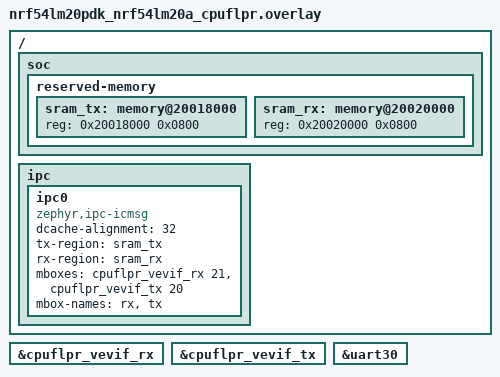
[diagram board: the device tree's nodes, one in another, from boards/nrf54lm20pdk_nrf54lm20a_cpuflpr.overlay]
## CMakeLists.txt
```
#
# Copyright (c) 2022 Nordic Semiconductor
#
# SPDX-License-Identifier: LicenseRef-Nordic-5-Clause
#

cmake_minimum_required(VERSION 3.20.0)

find_package(Zephyr REQUIRED HINTS $ENV{ZEPHYR_BASE})
project(event_manager_proxy_remote)

add_subdirectory("../common_events" "${CMAKE_CURRENT_BINARY_DIR}/common_events")
add_subdirectory("../modules"       "${CMAKE_CURRENT_BINARY_DIR}/modules")

target_sources(app PRIVATE src/main.c)
```

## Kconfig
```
#
# Copyright (c) 2022 Nordic Semiconductor ASA
#
# SPDX-License-Identifier: LicenseRef-Nordic-5-Clause
#

menu "Zephyr Kernel"
source "Kconfig.zephyr"
endmenu

menu "Event manager proxy sample application settings"
rsource "../common_events/Kconfig"
rsource "../modules/Kconfig"
endmenu
```

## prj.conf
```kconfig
#
# Copyright (c) 2022 Nordic Semiconductor ASA
#
# SPDX-License-Identifier: LicenseRef-Nordic-5-Clause
#
# Enabling assert
CONFIG_ASSERT=y

# Logger configuration
CONFIG_LOG=y
CONFIG_LOG_BACKEND_UART=y

# Configuration required by Event Manager
CONFIG_APP_EVENT_MANAGER=y
CONFIG_EVENT_MANAGER_PROXY=y
CONFIG_HEAP_MEM_POOL_SIZE=4096
CONFIG_REBOOT=y

CONFIG_PRINTK=y

CONFIG_IPC_SERVICE=y
CONFIG_MBOX=y

# Simplify debugging
CONFIG_RESET_ON_FATAL_ERROR=n

###################################
# Application configuration
###################################

CONFIG_APP_MODULE_CONTROLLER_ENABLE=y
CONFIG_APP_MODULE_SENSOR_SIMULATED_ENABLE=y
```

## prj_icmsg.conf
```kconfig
#
# Copyright (c) 2022 Nordic Semiconductor ASA
#
# SPDX-License-Identifier: LicenseRef-Nordic-5-Clause
#
# Enabling assert
CONFIG_ASSERT=y

# Logger configuration
CONFIG_LOG=y
CONFIG_LOG_DEFAULT_LEVEL=2
CONFIG_LOG_BACKEND_UART=y

# Configuration required by Event Manager
CONFIG_APP_EVENT_MANAGER=y
CONFIG_EVENT_MANAGER_PROXY=y
CONFIG_HEAP_MEM_POOL_SIZE=4096
CONFIG_REBOOT=y

CONFIG_PRINTK=y

CONFIG_IPC_SERVICE=y
CONFIG_MBOX=y

# Simplify debugging
CONFIG_RESET_ON_FATAL_ERROR=n

###################################
# Application configuration
###################################

CONFIG_APP_MODULE_CONTROLLER_ENABLE=y
CONFIG_APP_MODULE_SENSOR_SIMULATED_ENABLE=y
```

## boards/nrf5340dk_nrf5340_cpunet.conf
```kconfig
#
# Copyright (c) 2024 Nordic Semiconductor ASA
#
# SPDX-License-Identifier: LicenseRef-Nordic-5-Clause
#
################################################################################

CONFIG_OPENAMP_MASTER=n
```

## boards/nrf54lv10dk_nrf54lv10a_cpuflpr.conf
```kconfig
#
# Copyright (c) 2024 Nordic Semiconductor ASA
#
# SPDX-License-Identifier: LicenseRef-Nordic-5-Clause
#
################################################################################

CONFIG_LOG=y
CONFIG_LOG_MODE_MINIMAL=y
CONFIG_ASSERT=n
CONFIG_LOG_BACKEND_UART=n

CONFIG_BOOT_BANNER=n
CONFIG_EARLY_CONSOLE=y
CONFIG_HEAP_MEM_POOL_SIZE=1024

CONFIG_SIZE_OPTIMIZATIONS=y
```

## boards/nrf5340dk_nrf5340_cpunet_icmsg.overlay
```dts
/*
 * Copyright (c) 2022 Nordic Semiconductor ASA
 *
 * SPDX-License-Identifier: LicenseRef-Nordic-5-Clause
 */

/delete-node/ &ipc0;
/delete-node/ &sram0_shared;

/ {
	chosen {
		/delete-property/ zephyr,ipc_shm;
	};

	reserved-memory {
		#address-cells = <1>;
		#size-cells = <1>;

		sram_rx: memory@20070000 {
			reg = <0x20070000 0x0800>;
		};

		sram_tx: memory@20078000 {
			reg = <0x20078000 0x0800>;
		};
	};

	ipc0: ipc0 {
		compatible = "zephyr,ipc-icmsg";
		tx-region = <&sram_tx>;
		rx-region = <&sram_rx>;
		mboxes = <&mbox 0>, <&mbox 1>;
		mbox-names = "rx", "tx";
		status = "okay";
	};
};
```

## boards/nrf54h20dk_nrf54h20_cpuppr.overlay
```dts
/*
 * Copyright (c) 2024 Nordic Semiconductor ASA
 *
 * SPDX-License-Identifier: LicenseRef-Nordic-5-Clause
 */

/* Enabled nodes required by IPC
 * Two mboxes, one for each sides and one ipc instance
 */

&cpuppr_vevif {
	status = "okay";
};

&cpuapp_bellboard {
	status = "okay";
};

ipc0: &cpuapp_cpuppr_ipc {
	status = "okay";
};

&uart135 {
	/delete-property/ hw-flow-control;
};
```

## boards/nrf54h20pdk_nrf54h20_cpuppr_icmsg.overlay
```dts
/*
 * Copyright (c) 2024 Nordic Semiconductor ASA
 *
 * SPDX-License-Identifier: LicenseRef-Nordic-5-Clause
 */

/* Enabled nodes required by IPC
 * Two mboxes, one for each sides and one ipc instance
 */

&cpuppr_vevif {
	status = "okay";
};

&cpuapp_bellboard {
	status = "okay";
};

ipc0: &cpuapp_cpuppr_ipc {
	status = "okay";
};
```

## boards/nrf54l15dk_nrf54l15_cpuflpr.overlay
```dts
/*
 * Copyright (c) 2025 Nordic Semiconductor ASA
 *
 * SPDX-License-Identifier: LicenseRef-Nordic-5-Clause
 */

/ {
	reserved-memory {
		#address-cells = <1>;
		#size-cells = <1>;
		ranges;

		sram_tx: memory@20017c00 {
			reg = <0x20017c00 0x8000>;
		};

		sram_rx: memory@2001fc00 {
			reg = <0x2001fc00 0x8000>;
		};
	};

	ipc {
		ipc0: ipc0 {
			compatible = "zephyr,ipc-icmsg";
			/delete-property/ tx-blocks;
			/delete-property/ rx-blocks;
			dcache-alignment = <32>;
			tx-region = <&sram_tx>;
			rx-region = <&sram_rx>;
			mboxes = <&cpuflpr_vevif_rx 21>, <&cpuflpr_vevif_tx 20>;
			mbox-names = "rx", "tx";
			status = "okay";
		};
	};
};

&cpuflpr_vevif_rx {
	status = "okay";
};

&cpuflpr_vevif_tx {
	status = "okay";
};

&uart30 {
	/delete-property/ hw-flow-control;
};
```

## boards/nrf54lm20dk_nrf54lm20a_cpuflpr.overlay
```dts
/*
 * Copyright (c) 2025 Nordic Semiconductor ASA
 *
 * SPDX-License-Identifier: LicenseRef-Nordic-5-Clause
 */

/ {
	reserved-memory {
		ranges;
		#address-cells = <1>;
		#size-cells = <1>;

		sram_tx: memory@20057c00 {
			reg = <0x20057c00 0x8000>;
		};

		sram_rx: memory@2005fc00 {
			reg = <0x2005fc00 0x8000>;
		};
	};

	ipc {
		ipc0: ipc0 {
			compatible = "zephyr,ipc-icmsg";
			/delete-property/ tx-blocks;
			/delete-property/ rx-blocks;
			dcache-alignment = <32>;
			tx-region = <&sram_tx>;
			rx-region = <&sram_rx>;
			mboxes = <&cpuflpr_vevif_rx 21>, <&cpuflpr_vevif_tx 20>;
			mbox-names = "rx", "tx";
			status = "okay";
		};
	};
};

&cpuflpr_vevif_rx {
	status = "okay";
};

&cpuflpr_vevif_tx {
	status = "okay";
};

&uart30 {
	/delete-property/ hw-flow-control;
};
```

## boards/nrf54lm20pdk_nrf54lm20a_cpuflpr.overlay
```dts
/*
 * Copyright (c) 2025 Nordic Semiconductor ASA
 *
 * SPDX-License-Identifier: LicenseRef-Nordic-5-Clause
 */

/ {
	soc {
		reserved-memory {
			#address-cells = <1>;
			#size-cells = <1>;

			sram_tx: memory@20018000 {
				reg = <0x20018000 0x0800>;
			};

			sram_rx: memory@20020000 {
				reg = <0x20020000 0x0800>;
			};
		};
	};

	ipc {
		ipc0: ipc0 {
			compatible = "zephyr,ipc-icmsg";
			dcache-alignment = <32>;
			tx-region = <&sram_tx>;
			rx-region = <&sram_rx>;
			mboxes = <&cpuflpr_vevif_rx 21>, <&cpuflpr_vevif_tx 20>;
			mbox-names = "rx", "tx";
			status = "okay";
		};
	};
};

&cpuflpr_vevif_rx {
	status = "okay";
};

&cpuflpr_vevif_tx {
	status = "okay";
};

&uart30 {
	/delete-property/ hw-flow-control;
};
```

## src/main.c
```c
/*
 * Copyright (c) 2022 Nordic Semiconductor ASA
 *
 * SPDX-License-Identifier: LicenseRef-Nordic-5-Clause
 */

#include <zephyr/kernel.h>
#include <zephyr/device.h>

#include <zephyr/ipc/ipc_service.h>

#include <app_event_manager.h>
#include <event_manager_proxy.h>
#include <config_event.h>
#include <zephyr/logging/log.h>

#define MODULE main_remote

LOG_MODULE_REGISTER(MODULE);

int main(void)
{
	int ret;
	const struct device *ipc_instance  = DEVICE_DT_GET(DT_NODELABEL(ipc0));

	printk("Event Manager Proxy remote_core started\n");

	ret = app_event_manager_init();
	if (ret) {
		LOG_ERR("Event Manager not initialized, err: %d", ret);
		__ASSERT_NO_MSG(false);
		return 0;
	}
	LOG_INF("Event manager initialized");

	ret = event_manager_proxy_add_remote(ipc_instance);
	if (ret && ret != -EALREADY) {
		LOG_ERR("Cannot add remote: %d", ret);
		__ASSERT_NO_MSG(false);
		return 0;
	}
	LOG_INF("Event proxy remote added");

	/* Listen to the events from the remote */
	ret = EVENT_MANAGER_PROXY_SUBSCRIBE(ipc_instance, config_event);
	if (ret) {
		LOG_ERR("Cannot register to remote config_event: %d", ret);
		__ASSERT_NO_MSG(false);
		return 0;
	}
	LOG_INF("Event proxy config_event registered");

	ret = event_manager_proxy_start();
	if (ret) {
		LOG_ERR("Cannot start event manager proxy: %d", ret);
		__ASSERT_NO_MSG(false);
		return 0;
	}

	/* We do not have to wait for remotes here as we do not send any event that
	 * would be fatal when missed.
	 */
	LOG_INF("Initialization finished successfully");

	return 0;
}
```
